AUTOSAR XML (schema 00046)
package /Cluster
  can cluster Cluster0: baudrate=500000
    can physical channel Pch0
      frame message1: id 0x5, frame-length=6, can-addressing-mode=STANDARD  # Comment1
        pdu message1: length=6
          signal signal1: start 8, 3 bit, big-endian, system signal Signal1, compu {phys=raw*5 for raw 0..4}, unit=m
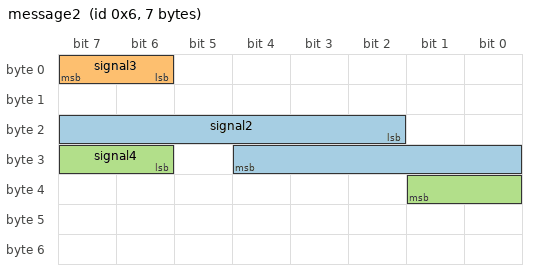
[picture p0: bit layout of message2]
      frame message2: id 0x6, frame-length=7, can-addressing-mode=EXTENDED
        pdu message2: length=7
          signal signal2: start 18, 11 bit, little-endian, system signal Signal2  # Signal comment!
          signal signal3: start 6, 2 bit, little-endian
          signal signal4: start 30, 4 bit, little-endian, system signal Signal4, compu {0..3, 1=one, 2=two}
      frame message3: id 0x64, frame-length=8, can-addressing-mode=STANDARD
        pdu message3: length=8
package /Unit
  unit meters: display-name=m
